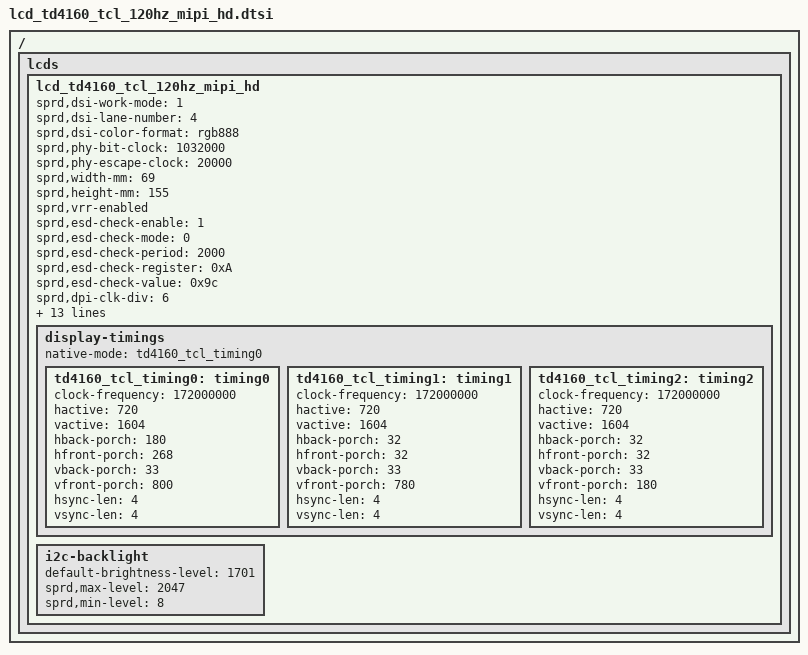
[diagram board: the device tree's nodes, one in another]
/ {
	fragment {
		target-path = "/";
		__overlay__ {
			lcds {
				lcd_td4160_tcl_120hz_mipi_hd: lcd_td4160_tcl_120hz_mipi_hd {

					sprd,dsi-work-mode = <1>; /* video burst mode*/
					sprd,dsi-lane-number = <4>;
					sprd,dsi-color-format = "rgb888";
					sprd,phy-bit-clock = <1032000>;
					sprd,phy-escape-clock = <20000>;/* kHz */
					sprd,width-mm = <69>;
					sprd,height-mm = <155>;
					sprd,vrr-enabled;
					sprd,esd-check-enable = <1>;
					sprd,esd-check-mode = <0>;
					sprd,esd-check-period = <2000>;
					sprd,esd-check-register = <0xA>;
					sprd,esd-check-value = <0x9c>;
					sprd,dpi-clk-div = <6>;
					sprd,video-lp-cmd-enable = <1>;
					sprd,hporch-lp-disable = <1>;

					sprd,reset-on-sequence = <1 15>, <0 5>, <1 15>;
					sprd,reset-off-sequence = <0 10>;
					ontim,tp-reset-flag;
					sprd,need-execute-shutdown;
					sprd,video-lp-en-mode = <11>;

					sprd,initial-command = [
						15 00 00 02 B0 04
						39 00 00 07 B8 06 90 27 00 31 80
						39 00 00 07 B9 06 8D 2A 00 2F 80
						39 00 00 07 BA 06 8C 2C 00 30 80
						39 00 00 03 C1 30 81
						39 00 00 19 CE 5D 6D 73 77 7C 82 84 90 9D B7 D0 E0 F0 FA FF FF FF 0C 00 04 04 00 03 6C
						15 00 00 02 D6 00
						39 00 00 03 51 07 FF
						15 00 00 02 53 24
						15 00 00 02 55 00
						05 78 00 01 11
						05 32 00 01 29
						];

					sprd,sleep-in-command = [
						05 1E 00 01 28
						05 32 00 01 10
						];
					sprd,sleep-out-command = [
						05 78 00 01 11
						05 32 00 01 29
						];

					display-timings {
						native-mode = <&td4160_tcl_timing0>;
						td4160_tcl_timing0: timing0 {
							clock-frequency = <172000000>;
							hactive = <720>;
							vactive = <1604>;
							hback-porch = <180>;
							hfront-porch = <268>;
							vback-porch = <33>;
							vfront-porch = <800>;
							hsync-len = <4>;
							vsync-len = <4>;
						};

						td4160_tcl_timing1: timing1 {
							clock-frequency = <172000000>;
							hactive = <720>;
							vactive = <1604>;
							hback-porch = <32>;
							hfront-porch = <32>;
							vback-porch = <33>;
							vfront-porch = <780>;
							hsync-len = <4>;
							vsync-len = <4>;
						};

						td4160_tcl_timing2: timing2 {
							clock-frequency = <172000000>;
							hactive = <720>;
							vactive = <1604>;
							hback-porch = <32>;
							hfront-porch = <32>;
							vback-porch = <33>;
							vfront-porch = <180>;
							hsync-len = <4>;
							vsync-len = <4>;
						};
					};
					i2c-backlight {
						default-brightness-level = <1701>;
						sprd,max-level = <2047>;
						sprd,min-level = <8>;
					};
				};
			};
		};
	};
};
